# SMS_HSM_CBASS_0_HSM_CBASS_ISC_4580A000h register map
Vendor: Texas Instruments
Peripheral module from a debugger description file (folder AM275x).
Registers are 32-bit, read-write, reset 0x0 unless marked. A register's access mark holds for its fields unless they carry their own. Offsets are as the file gives them; lines under a group give offsets from that group; [hi:lo] are bit positions; {n}, {i} and the like mark numbered series; 'fields as' and 'values as' point back to an identical list; <NAME> marks a mode.

## hsm_cbass_isc
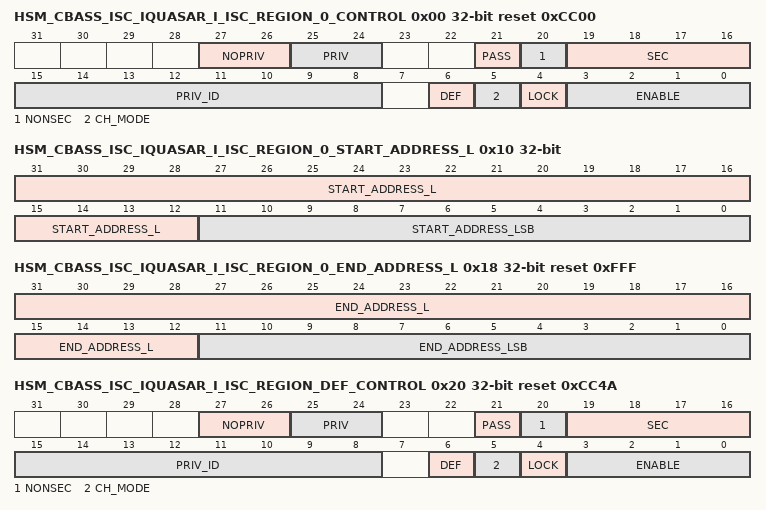
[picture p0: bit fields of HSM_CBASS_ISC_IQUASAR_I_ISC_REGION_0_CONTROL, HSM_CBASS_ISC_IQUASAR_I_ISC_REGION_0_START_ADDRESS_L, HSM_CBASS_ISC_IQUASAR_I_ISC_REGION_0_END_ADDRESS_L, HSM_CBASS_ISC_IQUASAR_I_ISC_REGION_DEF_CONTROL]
0x00 HSM_CBASS_ISC_IQUASAR_I_ISC_REGION_0_CONTROL access not given reset 0xCC00 — The ISC Region 0 Control Register defines the control fields for the initiator Iquasar_i.mst region 0 ISC.
  [27:26] NOPRIV rw — Clear output priv attribute. If each bit is set then the outgoing priv bit is cleared. Reset Source: sms_custom_rst_mod_g_rst_n
  [25:24] PRIV rw — Set outgoing priv attribute. If each bit is set then the outgoing priv bit is set. Reset Source: sms_custom_rst_mod_g_rst_n
  [21] PASS rw — No privID replacement, pass through value. Reset Source: sms_custom_rst_mod_g_rst_n
  [20] NONSEC rw — Make outgoing non-secure. Reset Source: sms_custom_rst_mod_g_rst_n
  [19:16] SEC rw — Make outgoing secure. A value of 0xA enables, others disable. Reset Source: sms_custom_rst_mod_g_rst_n
  [15:8] PRIV_ID rw — Priv ID. Reset Source: sms_custom_rst_mod_g_rst_n
  [6] DEF ro — Default region indication. The default region is used when all other regions do not match. Reset Source: sms_custom_rst_mod_g_rst_n
  [5] CH_MODE rw — Enable channel mode to match region to a chanid value. Otherwise use address mode to match region to an address range. Reset Source: sms_custom_rst_mod_g_rst_n
  [4] LOCK — Lock region. Once set the region values cannot be modified. Reset Source: sms_custom_rst_mod_g_rst_n (access R/W1TS)
  [3:0] ENABLE rw — Enable region. A value of 0xA enables, others disable. Reset Source: sms_custom_rst_mod_g_rst_n
0x10 HSM_CBASS_ISC_IQUASAR_I_ISC_REGION_0_START_ADDRESS_L — The ISC Region 0 Start Address Low Register defines the start address bits 31 to 0 for the initiator Iquasar_i.mst region 0 ISC.
  [31:12] START_ADDRESS_L — Start address bits 31 to 12. Reset Source: sms_custom_rst_mod_g_rst_n
  [11:0] START_ADDRESS_LSB — Start address bits 11 to 0 must be 0 as address must be 4KB aligned in address mode. Can also be channel number in channel mode. Reset Source: sms_custom_rst_mod_g_rst_n
0x14 HSM_CBASS_ISC_IQUASAR_I_ISC_REGION_0_START_ADDRESS_H — The ISC Region 0 Start Address High Register defines the start address bits 47 to 32 for the initiator Iquasar_i.mst region 0 ISC.
  [15:0] START_ADDRESS_H — Start address bits 47 to 32. Reset Source: sms_custom_rst_mod_g_rst_n
0x18 HSM_CBASS_ISC_IQUASAR_I_ISC_REGION_0_END_ADDRESS_L access per field reset 0xFFF — The ISC Region 0 End Address Low Register defines the end included address bits 31 to 0 for the initiator Iquasar_i.mst region 0 ISC.
  [31:12] END_ADDRESS_L rw — End address bits 31 to 12 to include in the match. Reset Source: sms_custom_rst_mod_g_rst_n
  [11:0] END_ADDRESS_LSB ro — End address bits 11 to 0 are forced to Fs as address must be 4KB aligned. Reset Source: sms_custom_rst_mod_g_rst_n
0x1C HSM_CBASS_ISC_IQUASAR_I_ISC_REGION_0_END_ADDRESS_H — The ISC Region 0 End Address High Register defines the end address bits 47 to 32 for the initiator Iquasar_i.mst region 0 ISC.
  [15:0] END_ADDRESS_H — End address bits 47 to 32. Reset Source: sms_custom_rst_mod_g_rst_n
0x20 HSM_CBASS_ISC_IQUASAR_I_ISC_REGION_DEF_CONTROL access not given reset 0xCC4A — The ISC Default Region Control Register defines the control fields for the initiator Iquasar_i.mst region 1 ISC.
  [27:26] NOPRIV rw — Clear output priv attribute. If each bit is set then the outgoing priv bit is cleared, else the bit is unchanged. Do not set both priv and nopriv for the same bit. Reset Source: sms_custom_rst_mod_g_rst_n
  [25:24] PRIV rw — Set outgoing priv attribute. If each bit is set then the outgoing priv bit is set, else the bit is unchanged. Do not set both priv and nopriv for the same bit. Reset Source: sms_custom_rst_mod_g_rst_n
  [21] PASS rw — No privID replacement. A value of 1 will pass through privid value. A value of 0 will replace privid with priv_id field value. Reset Source: sms_custom_rst_mod_g_rst_n
  [20] NONSEC rw — Make outgoing non-secure. A value of 1 forces secure clear, others do nothing. Do not set both sec and nonsec. Reset Source: sms_custom_rst_mod_g_rst_n
  [19:16] SEC rw — Make outgoing secure. A value of 0xA forces secure set, others do nothing. Do not set both sec and nonsec. Reset Source: sms_custom_rst_mod_g_rst_n
  [15:8] PRIV_ID rw — Priv ID value to use if pass is 0. Reset Source: sms_custom_rst_mod_g_rst_n
  [6] DEF ro — Default region indication. The default region is used when all other regions do not match. Reset Source: sms_custom_rst_mod_g_rst_n
  [5] CH_MODE ro — Enable channel mode to match region to a chanid value. Otherwise use address mode to match region to an address range. Reset Source: sms_custom_rst_mod_g_rst_n
  [4] LOCK — Lock region. Once set, the region values cannot be modified. Reset Source: sms_custom_rst_mod_g_rst_n (access R/W1TS)
  [3:0] ENABLE ro — Enable region. A value of 0xA enables, others disable. Reset Source: sms_custom_rst_mod_g_rst_n
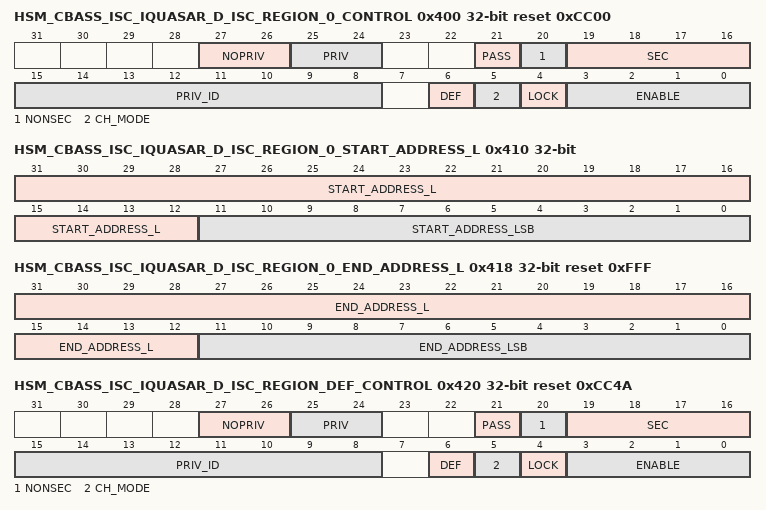
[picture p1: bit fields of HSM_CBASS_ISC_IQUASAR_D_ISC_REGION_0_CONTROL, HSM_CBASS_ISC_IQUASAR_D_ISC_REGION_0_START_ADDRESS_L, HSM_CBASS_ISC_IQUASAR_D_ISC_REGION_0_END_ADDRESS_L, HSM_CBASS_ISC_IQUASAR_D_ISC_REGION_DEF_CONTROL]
0x400 HSM_CBASS_ISC_IQUASAR_D_ISC_REGION_0_CONTROL access not given reset 0xCC00 — The ISC Region 0 Control Register defines the control fields for the initiator Iquasar_d.mst region 0 ISC.
  fields as HSM_CBASS_ISC_IQUASAR_I_ISC_REGION_0_CONTROL
0x410 HSM_CBASS_ISC_IQUASAR_D_ISC_REGION_0_START_ADDRESS_L — The ISC Region 0 Start Address Low Register defines the start address bits 31 to 0 for the initiator Iquasar_d.mst region 0 ISC.
  fields as HSM_CBASS_ISC_IQUASAR_I_ISC_REGION_0_START_ADDRESS_L
0x414 HSM_CBASS_ISC_IQUASAR_D_ISC_REGION_0_START_ADDRESS_H — The ISC Region 0 Start Address High Register defines the start address bits 47 to 32 for the initiator Iquasar_d.mst region 0 ISC.
  fields as HSM_CBASS_ISC_IQUASAR_I_ISC_REGION_0_START_ADDRESS_H
0x418 HSM_CBASS_ISC_IQUASAR_D_ISC_REGION_0_END_ADDRESS_L access per field reset 0xFFF — The ISC Region 0 End Address Low Register defines the end included address bits 31 to 0 for the initiator Iquasar_d.mst region 0 ISC.
  fields as HSM_CBASS_ISC_IQUASAR_I_ISC_REGION_0_END_ADDRESS_L
0x41C HSM_CBASS_ISC_IQUASAR_D_ISC_REGION_0_END_ADDRESS_H — The ISC Region 0 End Address High Register defines the end address bits 47 to 32 for the initiator Iquasar_d.mst region 0 ISC.
  fields as HSM_CBASS_ISC_IQUASAR_I_ISC_REGION_0_END_ADDRESS_H
0x420 HSM_CBASS_ISC_IQUASAR_D_ISC_REGION_DEF_CONTROL access not given reset 0xCC4A — The ISC Default Region Control Register defines the control fields for the initiator Iquasar_d.mst region 1 ISC.
  fields as HSM_CBASS_ISC_IQUASAR_I_ISC_REGION_DEF_CONTROL
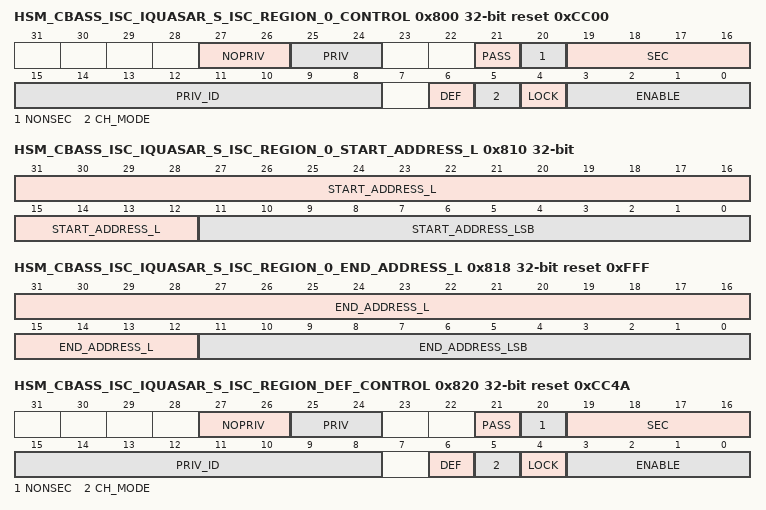
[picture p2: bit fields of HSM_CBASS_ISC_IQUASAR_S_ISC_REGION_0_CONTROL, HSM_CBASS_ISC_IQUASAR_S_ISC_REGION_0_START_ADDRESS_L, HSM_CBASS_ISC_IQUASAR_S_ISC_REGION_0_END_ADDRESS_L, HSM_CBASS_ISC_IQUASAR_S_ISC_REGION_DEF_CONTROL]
0x800 HSM_CBASS_ISC_IQUASAR_S_ISC_REGION_0_CONTROL access not given reset 0xCC00 — The ISC Region 0 Control Register defines the control fields for the initiator Iquasar_s.mst region 0 ISC.
  fields as HSM_CBASS_ISC_IQUASAR_I_ISC_REGION_0_CONTROL
0x810 HSM_CBASS_ISC_IQUASAR_S_ISC_REGION_0_START_ADDRESS_L — The ISC Region 0 Start Address Low Register defines the start address bits 31 to 0 for the initiator Iquasar_s.mst region 0 ISC.
  fields as HSM_CBASS_ISC_IQUASAR_I_ISC_REGION_0_START_ADDRESS_L
0x814 HSM_CBASS_ISC_IQUASAR_S_ISC_REGION_0_START_ADDRESS_H — The ISC Region 0 Start Address High Register defines the start address bits 47 to 32 for the initiator Iquasar_s.mst region 0 ISC.
  fields as HSM_CBASS_ISC_IQUASAR_I_ISC_REGION_0_START_ADDRESS_H
0x818 HSM_CBASS_ISC_IQUASAR_S_ISC_REGION_0_END_ADDRESS_L access per field reset 0xFFF — The ISC Region 0 End Address Low Register defines the end included address bits 31 to 0 for the initiator Iquasar_s.mst region 0 ISC.
  fields as HSM_CBASS_ISC_IQUASAR_I_ISC_REGION_0_END_ADDRESS_L
0x81C HSM_CBASS_ISC_IQUASAR_S_ISC_REGION_0_END_ADDRESS_H — The ISC Region 0 End Address High Register defines the end address bits 47 to 32 for the initiator Iquasar_s.mst region 0 ISC.
  fields as HSM_CBASS_ISC_IQUASAR_I_ISC_REGION_0_END_ADDRESS_H
0x820 HSM_CBASS_ISC_IQUASAR_S_ISC_REGION_DEF_CONTROL access not given reset 0xCC4A — The ISC Default Region Control Register defines the control fields for the initiator Iquasar_s.mst region 1 ISC.
  fields as HSM_CBASS_ISC_IQUASAR_I_ISC_REGION_DEF_CONTROL
